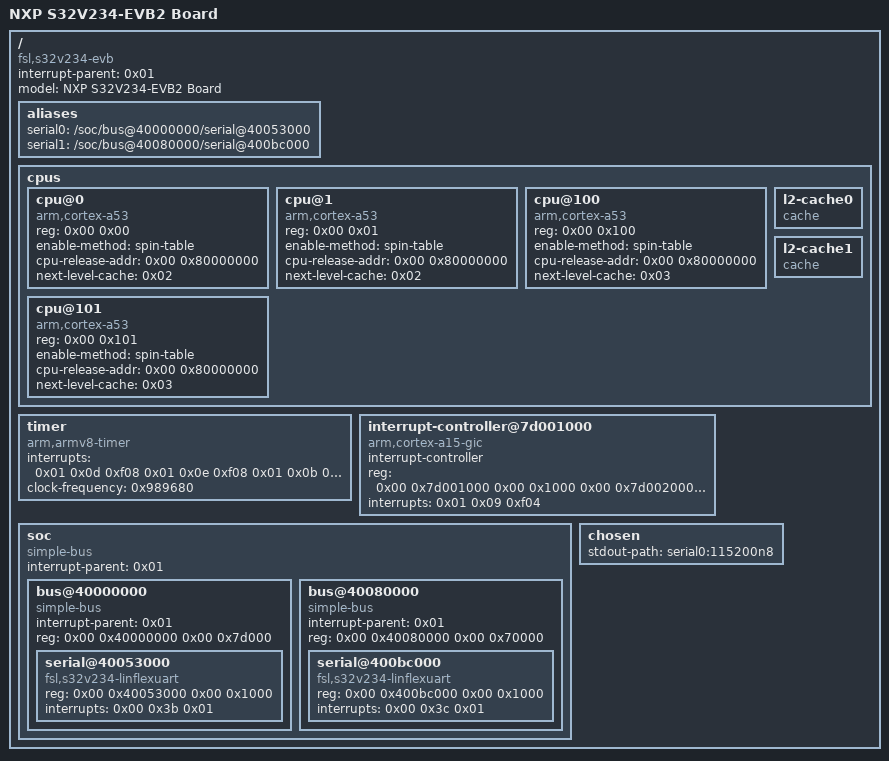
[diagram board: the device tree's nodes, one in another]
/dts-v1/;

/memreserve/	0x0000000080000000 0x0000000000010000;
/ {
	compatible = "fsl,s32v234-evb\0fsl,s32v234";
	interrupt-parent = <0x01>;
	#address-cells = <0x02>;
	#size-cells = <0x02>;
	model = "NXP S32V234-EVB2 Board";

	aliases {
		serial0 = "/soc/bus@40000000/serial@40053000";
		serial1 = "/soc/bus@40080000/serial@400bc000";
	};

	cpus {
		#address-cells = <0x02>;
		#size-cells = <0x00>;

		cpu@0 {
			device_type = "cpu";
			compatible = "arm,cortex-a53";
			reg = <0x00 0x00>;
			enable-method = "spin-table";
			cpu-release-addr = <0x00 0x80000000>;
			next-level-cache = <0x02>;
			phandle = <0x04>;
		};

		cpu@1 {
			device_type = "cpu";
			compatible = "arm,cortex-a53";
			reg = <0x00 0x01>;
			enable-method = "spin-table";
			cpu-release-addr = <0x00 0x80000000>;
			next-level-cache = <0x02>;
			phandle = <0x05>;
		};

		cpu@100 {
			device_type = "cpu";
			compatible = "arm,cortex-a53";
			reg = <0x00 0x100>;
			enable-method = "spin-table";
			cpu-release-addr = <0x00 0x80000000>;
			next-level-cache = <0x03>;
			phandle = <0x06>;
		};

		cpu@101 {
			device_type = "cpu";
			compatible = "arm,cortex-a53";
			reg = <0x00 0x101>;
			enable-method = "spin-table";
			cpu-release-addr = <0x00 0x80000000>;
			next-level-cache = <0x03>;
			phandle = <0x07>;
		};

		l2-cache0 {
			compatible = "cache";
			phandle = <0x02>;
		};

		l2-cache1 {
			compatible = "cache";
			phandle = <0x03>;
		};
	};

	timer {
		compatible = "arm,armv8-timer";
		interrupts = <0x01 0x0d 0xf08 0x01 0x0e 0xf08 0x01 0x0b 0xf08 0x01 0x0a 0xf08>;
		clock-frequency = <0x989680>;
	};

	interrupt-controller@7d001000 {
		compatible = "arm,cortex-a15-gic\0arm,cortex-a9-gic";
		#interrupt-cells = <0x03>;
		#address-cells = <0x00>;
		interrupt-controller;
		reg = <0x00 0x7d001000 0x00 0x1000 0x00 0x7d002000 0x00 0x2000 0x00 0x7d004000 0x00 0x2000 0x00 0x7d006000 0x00 0x2000>;
		interrupts = <0x01 0x09 0xf04>;
		phandle = <0x01>;
	};

	soc {
		#address-cells = <0x02>;
		#size-cells = <0x02>;
		compatible = "simple-bus";
		interrupt-parent = <0x01>;
		ranges;

		bus@40000000 {
			compatible = "simple-bus";
			#address-cells = <0x02>;
			#size-cells = <0x02>;
			interrupt-parent = <0x01>;
			reg = <0x00 0x40000000 0x00 0x7d000>;
			ranges;
			phandle = <0x08>;

			serial@40053000 {
				compatible = "fsl,s32v234-linflexuart";
				reg = <0x00 0x40053000 0x00 0x1000>;
				interrupts = <0x00 0x3b 0x01>;
				status = "okay";
				phandle = <0x09>;
			};
		};

		bus@40080000 {
			compatible = "simple-bus";
			#address-cells = <0x02>;
			#size-cells = <0x02>;
			interrupt-parent = <0x01>;
			reg = <0x00 0x40080000 0x00 0x70000>;
			ranges;
			phandle = <0x0a>;

			serial@400bc000 {
				compatible = "fsl,s32v234-linflexuart";
				reg = <0x00 0x400bc000 0x00 0x1000>;
				interrupts = <0x00 0x3c 0x01>;
				status = "okay";
				phandle = <0x0b>;
			};
		};
	};

	chosen {
		stdout-path = "serial0:115200n8";
	};

	__symbols__ {
		cpu0 = "/cpus/cpu@0";
		cpu1 = "/cpus/cpu@1";
		cpu2 = "/cpus/cpu@100";
		cpu3 = "/cpus/cpu@101";
		cluster0_l2_cache = "/cpus/l2-cache0";
		cluster1_l2_cache = "/cpus/l2-cache1";
		gic = "/interrupt-controller@7d001000";
		aips0 = "/soc/bus@40000000";
		uart0 = "/soc/bus@40000000/serial@40053000";
		aips1 = "/soc/bus@40080000";
		uart1 = "/soc/bus@40080000/serial@400bc000";
	};
};
